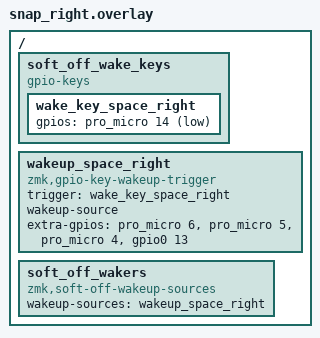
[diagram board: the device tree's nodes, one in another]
/*
 * Wake the right half (peripheral) from &soft_off with the right Space key.
 *
 * Same approach as snap_left.overlay: select the key's demux column, keep the
 * 3.3 V rail on for the demux chip, and arm the key's row pin as a wake interrupt.
 * Right Space is RC(5,15) in the transform = local column 7 (col-offset 8),
 * so all three address lines (pro_micro 6/5/4) are driven high; row 5 is pro_micro 14.
 * Only active during soft-off; normal scanning is unaffected.
 */

#include <dt-bindings/gpio/gpio.h>

/ {
    soft_off_wake_keys {
        compatible = "gpio-keys";
        wake_key_space_right: wake_key_space_right {
            gpios = <&pro_micro 14 (GPIO_ACTIVE_LOW | GPIO_PULL_UP)>;
        };
    };

    wakeup_space_right: wakeup_space_right {
        compatible = "zmk,gpio-key-wakeup-trigger";
        trigger = <&wake_key_space_right>;
        wakeup-source;
        extra-gpios = <&pro_micro 6 GPIO_ACTIVE_HIGH>,  // demux A0 = 1
                      <&pro_micro 5 GPIO_ACTIVE_HIGH>,  // demux A1 = 1
                      <&pro_micro 4 GPIO_ACTIVE_HIGH>,  // demux A2 = 1  -> column 7
                      <&gpio0 13 GPIO_ACTIVE_HIGH>;     // keep VCC (ext power) on
    };

    soft_off_wakers {
        compatible = "zmk,soft-off-wakeup-sources";
        wakeup-sources = <&wakeup_space_right>;
    };
};
